# MCU_CTRL_MMR0_CFG0 register map
Vendor: Texas Instruments
Peripheral module from a debugger description file (folder J7VCL).
Registers are 32-bit, access per field, reset 0x0 unless marked. A register's access mark holds for its fields unless they carry their own. Offsets are as the file gives them; lines under a group give offsets from that group; [hi:lo] are bit positions; {n}, {i} and the like mark numbered series; 'fields as' and 'values as' point back to an identical list; <NAME> marks a mode.

## MCU_CTRL_MMR0_CFG0
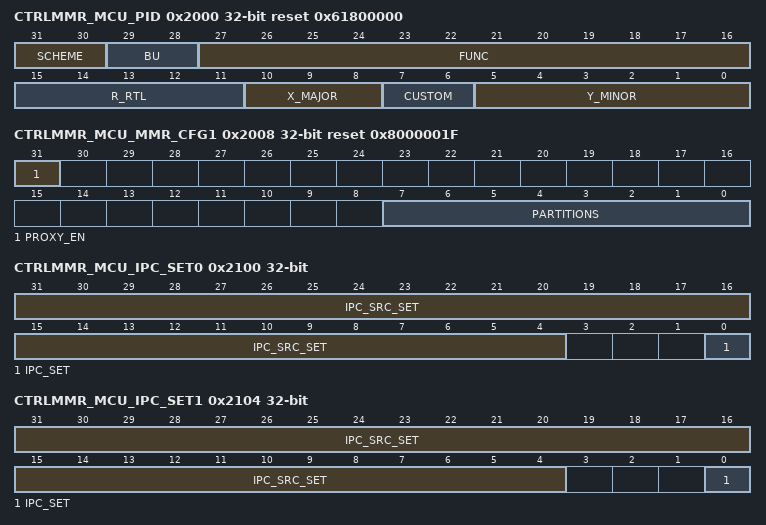
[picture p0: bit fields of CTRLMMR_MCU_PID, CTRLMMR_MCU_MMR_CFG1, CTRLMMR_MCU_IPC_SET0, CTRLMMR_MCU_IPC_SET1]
0x2000 CTRLMMR_MCU_PID ro reset 0x61800000
  [31:30] SCHEME
  [29:28] BU — Business unit - Processors
  [27:16] FUNC — Module functional identifier - CTRL MMR
  [15:11] R_RTL — RTL revision number
  [10:8] X_MAJOR — Major revision number
  [7:6] CUSTOM — Custom revision number
  [5:0] Y_MINOR — Minor revision number
0x2008 CTRLMMR_MCU_MMR_CFG1 ro reset 0x8000001F
  [31] PROXY_EN — Proxy addressing enabled
  [7:0] PARTITIONS — Indicates present partitions
0x2100 CTRLMMR_MCU_IPC_SET0 access not given
  [31:4] IPC_SRC_SET — Read returns current value (access W1TS)
  [0] IPC_SET — Read returns 0 (access W1TS)
0x2104 CTRLMMR_MCU_IPC_SET1 access not given
  fields as CTRLMMR_MCU_IPC_SET0
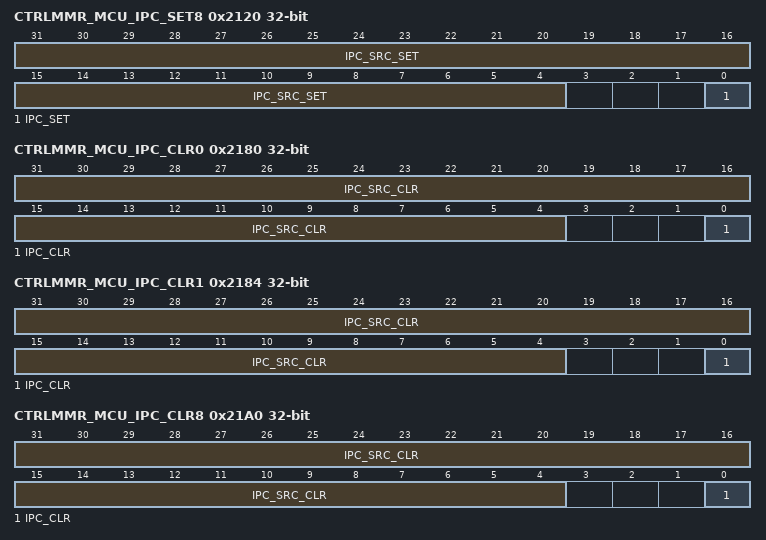
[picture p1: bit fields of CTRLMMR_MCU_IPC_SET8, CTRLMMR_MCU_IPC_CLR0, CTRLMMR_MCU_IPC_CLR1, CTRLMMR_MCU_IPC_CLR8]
0x2120 CTRLMMR_MCU_IPC_SET8 access not given
  fields as CTRLMMR_MCU_IPC_SET0
0x2180 CTRLMMR_MCU_IPC_CLR0 access not given
  [31:4] IPC_SRC_CLR — Read returns current value (access W1TC)
  [0] IPC_CLR — Read returns current value (access W1TC)
0x2184 CTRLMMR_MCU_IPC_CLR1 access not given
  fields as CTRLMMR_MCU_IPC_CLR0
0x21A0 CTRLMMR_MCU_IPC_CLR8 access not given
  fields as CTRLMMR_MCU_IPC_CLR0
0x2200 CTRLMMR_MCU_MAC_ID0 access not given reset not defined
  [31:0] MACID_LO — 32 lsbs of MAC address (access WOT)
0x2204 CTRLMMR_MCU_MAC_ID1 access not given (reset mask 0xFFFF0000)
  [15:0] MACID_HI — 16 msbs of MAC address (access WOT)
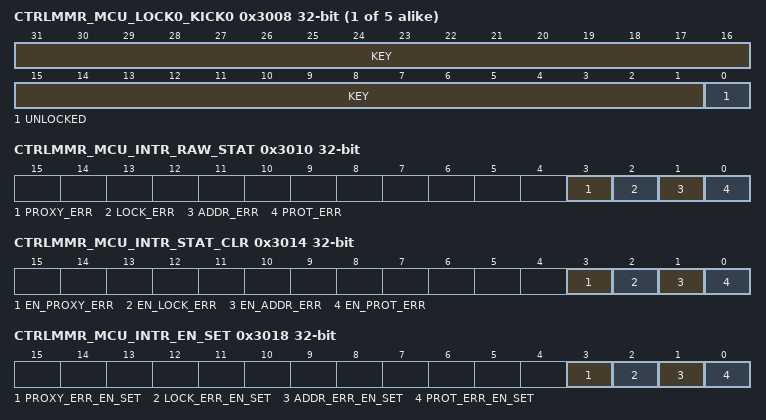
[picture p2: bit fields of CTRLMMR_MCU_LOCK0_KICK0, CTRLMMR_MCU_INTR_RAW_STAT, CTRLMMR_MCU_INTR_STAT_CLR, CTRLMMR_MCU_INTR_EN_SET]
{0x3008+0x4000*i} CTRLMMR_MCU_LOCK{i}_KICK0 (i=0..4)
  [31:1] KEY rw — Write the kick0 unlock value followed by the kick1 unlock value to unlock the write-protected Partition{i} registers
  [0] UNLOCKED ro — Unlock status. When set indicates that the proper unlock sequence has been performed and the partition is unlocked for writing.
{0x300C+0x4000*i} CTRLMMR_MCU_LOCK{i}_KICK1 rw (i=0..4)
  [31:0] KEY — Write the kick1 unlock value after the kick0 unlock value to unlock the write-protected Partition{i} registers
0x3010 CTRLMMR_MCU_INTR_RAW_STAT access not given
  [3] PROXY_ERR — Proxy violation occurred (attempt to write a Proxy1 claimed register through its Proxy0 address) (access W1TS)
  [2] LOCK_ERR — Lock violation occurred (attempt to write a write-locked register with partition locked) (access W1TS)
  [1] ADDR_ERR — Address violation occurred (attempt to read or write an invalid register address) (access W1TS)
  [0] PROT_ERR — Protection violation occurred (attempt to read or write a register with insufficient security or privilege access rights) (access W1TS)
0x3014 CTRLMMR_MCU_INTR_STAT_CLR access not given
  [3] EN_PROXY_ERR — Enabled proxy interrupt event status (access W1TC)
  [2] EN_LOCK_ERR — Enabled lock interrupt event status (access W1TC)
  [1] EN_ADDR_ERR — Enabled address interrupt event status (access W1TC)
  [0] EN_PROT_ERR — Enabled protection interrupt event status (access W1TC)
0x3018 CTRLMMR_MCU_INTR_EN_SET access not given
  [3] PROXY_ERR_EN_SET — Proxy interrupt enable (access W1TS)
  [2] LOCK_ERR_EN_SET — Lock interrupt enable (access W1TS)
  [1] ADDR_ERR_EN_SET — Address interrupt enable (access W1TS)
  [0] PROT_ERR_EN_SET — Protection interrupt enable (access W1TS)
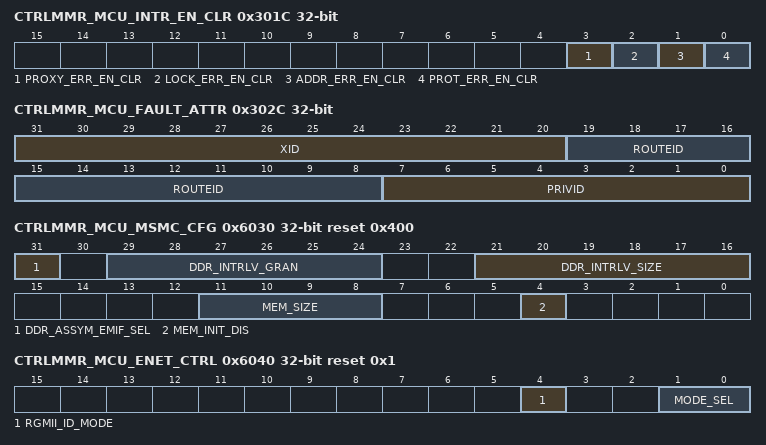
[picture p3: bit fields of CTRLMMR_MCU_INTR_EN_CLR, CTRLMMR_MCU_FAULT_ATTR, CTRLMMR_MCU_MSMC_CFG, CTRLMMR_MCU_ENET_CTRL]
0x301C CTRLMMR_MCU_INTR_EN_CLR access not given
  [3] PROXY_ERR_EN_CLR — Proxy interrupt disable (access W1TC)
  [2] LOCK_ERR_EN_CLR — Lock interrupt disable (access W1TC)
  [1] ADDR_ERR_EN_CLR — Address interrupt disable (access W1TC)
  [0] PROT_ERR_EN_CLR — Protection interrupt disable (access W1TC)
0x3020 CTRLMMR_MCU_EOI
  [7:0] VECTOR rw
0x3024 CTRLMMR_MCU_FAULT_ADDR ro
  [31:0] ADDRESS — Address of the faulted access
0x3028 CTRLMMR_MCU_FAULT_TYPE ro
  [5:0] TYPE — Type of access which faulted 0h - No fault 1h - User execute access 2h - User write access 4h - User read access 8h - Supervisor execute access 10h - Supervisor write access 20h - Supervisor read access
0x302C CTRLMMR_MCU_FAULT_ATTR ro
  [31:20] XID — Transaction ID
  [19:8] ROUTEID
  [7:0] PRIVID — Privilege ID
0x3030 CTRLMMR_MCU_FAULT_CLR access not given
  [0] CLEAR — Fault clear (access W1TC)
{0x3100+4i} CTRLMMR_MCU_P0_CLAIM{i} rw (i=0..4)
  [31:0] PROXY1_CLAIMED — Proxy1 register claim bit
0x6030 CTRLMMR_MCU_MSMC_CFG reset 0x400
  [31] DDR_ASSYM_EMIF_SEL rw — In the asymmetric interleave, controls which EMIF controller implements the separated range of the memory window
  [29:24] DDR_INTRLV_GRAN rw — Defines the size of each memory stripe for interleaved memory space
  [21:16] DDR_INTRLV_SIZE rw — Defines the memory window size for the interleaved region starting at the bottom of the external memory address range.
  [11:8] MEM_SIZE ro — Indicates the size of MSMC shared SRAM/Cache 0h - 0.0 MB 1h - 0.25 MB 2h - 0.5 MB 3h - 0.75 MB 4h - 1.0 MB 5h - 1.25 MB 6h - 1.5 MB 7h - 1.75 MB 8h - 2.0 MB
  [4] MEM_INIT_DIS rw — Disables MSMC SRAM initialization (Data, Cache Tags, and Snoop Filters). This is required for proper initial ECC initialization.
0x6040 CTRLMMR_MCU_ENET_CTRL reset 0x1
  [4] RGMII_ID_MODE rw — Port1 RGMII internal transmit delay selection
  [1:0] MODE_SEL rw — Selects Ethernet switch Port1 interface 0h - GMII/MII (not supported) 1h - RMII 2h - RGMII 3h - SGMII (not supported)
0x6060 CTRLMMR_MCU_SPI1_CTRL
  [0] SPI1_LINKDIS rw — Disables direct connection of MCU_SPI1 to SPI3 0h - MCU_SPI1 is tied as a slave to SPI3. MCU_SPI1 CLK, DATA1 and CS0 are driven from SPI3, DATA OUT drives SPI3 DATA0 1h - MCU_SPI1 is NOT tied as a slave to SPI3. MCU_SPI1 CLK, DATA0, DATA1 and CS[3:0] are controlled through their respective MCU_SPI1 pins and SPI3 CLK, DATA0, DATA1, and CS[3:0] are controlled through their respective SPI3 pins.
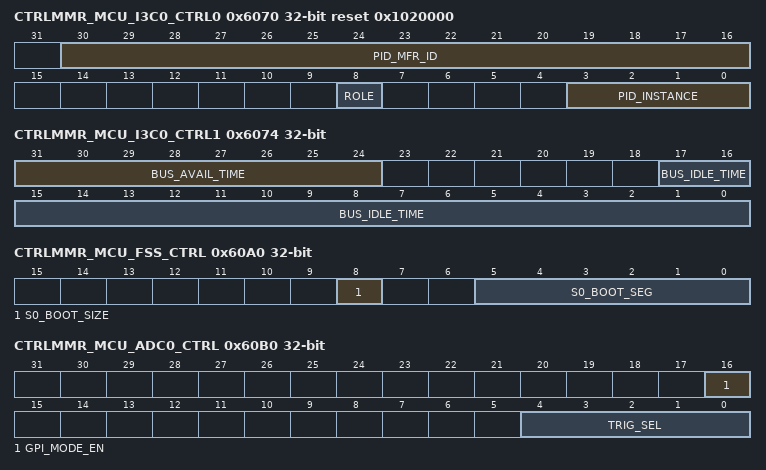
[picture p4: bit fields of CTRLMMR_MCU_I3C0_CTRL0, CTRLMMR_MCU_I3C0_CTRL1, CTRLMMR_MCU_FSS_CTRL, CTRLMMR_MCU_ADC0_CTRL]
0x6070 CTRLMMR_MCU_I3C0_CTRL0 reset 0x1020000
  [30:16] PID_MFR_ID rw — Manufacturer ID
  [8] ROLE rw — Master Role
  [3:0] PID_INSTANCE rw — Provisional ID Instance. This input corresponds to bits[15:12] of the Provisional ID. It is intended to provide a way of differentiating several I3C devices if there would be no other way to have each manufactured device have a unique Provisional ID
0x6074 CTRLMMR_MCU_I3C0_CTRL1
  [31:24] BUS_AVAIL_TIME rw — Indicates the number of pclk cycles in the Bus Available condition
  [17:0] BUS_IDLE_TIME rw — Indicates the number of pclk cycles in the Bus Idle condition
0x6080 CTRLMMR_MCU_I2C0_CTRL
  [0] HS_MCS_EN rw — HS Mode master current source enable.
0x6084 CTRLMMR_MCU_I2C1_CTRL
  [0] HS_MCS_EN rw — HS Mode master current source enable.
0x60A0 CTRLMMR_MCU_FSS_CTRL
  [8] S0_BOOT_SIZE rw — Selects the size of the boot block to be used for the S0 (OSPI0 or Hyperbus) flash interface
  [5:0] S0_BOOT_SEG rw — Selects the boot block to be used for the S0 (OSPI0 or Hyperbus) flash interface. If the s0_boot_size is 128 MB then only bits [4:0] of this field are used. Care must be taken to account for the address translation as to not fall off or wrap the address of the flash. (e.g. if both ECC and authentication are enabled for 64 MB boot, the highest valid block number is 49, as sector 50 is only .2M Bytes in size.)
0x60B0 CTRLMMR_MCU_ADC0_CTRL
  [16] GPI_MODE_EN rw — Enables MCU_ADC0 data pins to be used as general purpose inputs when set. This signal is tied to the en_dig_test input of MCU_ADC0
  [4:0] TRIG_SEL rw — Selects the source of the ADC hardware event trigger 0h - MCU_ADC_EXT_TRIGGER0 pin 1h - MCU_ADC_EXT_TRIGGER1 pin 2h - eHRPWM SOCA event 3h - eHRPWM SOCB event 4h - MCU Timer0 PWM output 5h - MCU Timer1 PWM output 6h - MCU Timer2 PWM output 7h - MCU Timer3 PWM output 8h - Timer0 PWM output 9h - Timer1 PWM output Ah - Timer2 PWM output Bh - Timer3 PWM output Ch - Timer4 PWM output Dh - Timer5 PWM output Eh - Timer6 PWM output Fh - Timer7 PWM output 10h - Timer8 PWM output 11h - Timer9 PWM output 12h - Timer10 PWM output 13h - Timer11 PWM output 15h - Reserved (tied 0h) 16h - Reserved (tied 0h) 18h - MCU Timer4 PWM output 19h - MCU Timer5 PWM output 1Ah - MCU Timer6 PWM output 1Bh - MCU Timer7 PWM output 1Ch - MCU Timer8 PWM output 1Dh - MCU Timer9 PWM output 1Eh - Reserved (tied 0h) 1Fh - Reserved (tied 0h)
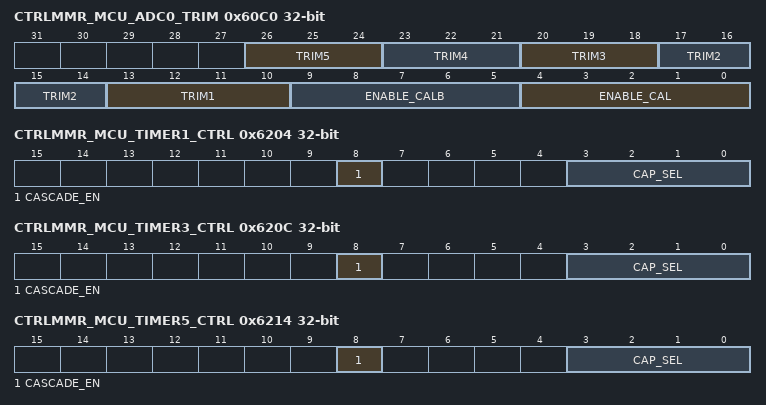
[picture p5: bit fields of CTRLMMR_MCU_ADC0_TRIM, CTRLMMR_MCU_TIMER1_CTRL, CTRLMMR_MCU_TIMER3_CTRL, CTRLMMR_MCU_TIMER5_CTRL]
0x60C0 CTRLMMR_MCU_ADC0_TRIM (reset mask 0xF8000000)
  [26:24] TRIM5 rw — Refer to AFE specification
  [23:21] TRIM4 rw — Refer to AFE specification
  [20:18] TRIM3 rw — Refer to AFE specification
  [17:14] TRIM2 rw — Refer to AFE specification
  [13:10] TRIM1 rw — Refer to AFE specification
  [9:5] ENABLE_CALB rw — Refer to AFE specification
  [4:0] ENABLE_CAL rw — Refer to AFE specification
0x6200 CTRLMMR_MCU_TIMER0_CTRL
  [3:0] CAP_SEL rw — Selects the MCU_TIMERIO input pin for capture input signal. This control is only used when TIMER0 is configured for capture operation. 0h - Use MCU_TIMER_IO0 pin 1h - Use MCU_TIMER_IO1 pin 2h - Use MCU_TIMER_IO2 pin 3h - Use MCU_TIMER_IO3 pin 4h - Use MCU_TIMER_IO4 pin 5h - Use MCU_TIMER_IO5 pin 6h - Use MCU_TIMER_IO6 pin 7h - Use MCU_TIMER_IO7 pin 8h - Use MCU_TIMER_IO8 pin 9h - Use MCU_TIMER_IO9 pin
0x6204 CTRLMMR_MCU_TIMER1_CTRL
  [8] CASCADE_EN rw — When set, enables cascading of MCU_TIMER1 to MCU_TIMER0
  [3:0] CAP_SEL rw — Selects the MCU_TIMERIO input pin for capture input signal. This control is only used when TIMER1 is configured for capture operation. 0h - Use MCU_TIMER_IO0 pin 1h - Use MCU_TIMER_IO1 pin 2h - Use MCU_TIMER_IO2 pin 3h - Use MCU_TIMER_IO3 pin 4h - Use MCU_TIMER_IO4 pin 5h - Use MCU_TIMER_IO5 pin 6h - Use MCU_TIMER_IO6 pin 7h - Use MCU_TIMER_IO7 pin 8h - Use MCU_TIMER_IO8 pin 9h - Use MCU_TIMER_IO9 pin
0x6208 CTRLMMR_MCU_TIMER2_CTRL
  [3:0] CAP_SEL rw — Selects the MCU_TIMERIO input pin for capture input signal. This control is only used when TIMER2 is configured for capture operation. 0h - Use MCU_TIMER_IO0 pin 1h - Use MCU_TIMER_IO1 pin 2h - Use MCU_TIMER_IO2 pin 3h - Use MCU_TIMER_IO3 pin 4h - Use MCU_TIMER_IO4 pin 5h - Use MCU_TIMER_IO5 pin 6h - Use MCU_TIMER_IO6 pin 7h - Use MCU_TIMER_IO7 pin 8h - Use MCU_TIMER_IO8 pin 9h - Use MCU_TIMER_IO9 pin
0x620C CTRLMMR_MCU_TIMER3_CTRL
  [8] CASCADE_EN rw — When set, enables cascading of MCU_TIMER3 to MCU_TIMER2
  [3:0] CAP_SEL rw — Selects the MCU_TIMERIO input pin for capture input signal. This control is only used when TIMER3 is configured for capture operation. 0h - Use MCU_TIMER_IO0 pin 1h - Use MCU_TIMER_IO1 pin 2h - Use MCU_TIMER_IO2 pin 3h - Use MCU_TIMER_IO3 pin 4h - Use MCU_TIMER_IO4 pin 5h - Use MCU_TIMER_IO5 pin 6h - Use MCU_TIMER_IO6 pin 7h - Use MCU_TIMER_IO7 pin 8h - Use MCU_TIMER_IO8 pin 9h - Use MCU_TIMER_IO9 pin
0x6210 CTRLMMR_MCU_TIMER4_CTRL
  [3:0] CAP_SEL rw — Selects the MCU_TIMERIO input pin for capture input signal. This control is only used when TIMER4 is configured for capture operation. 0h - Use MCU_TIMER_IO0 pin 1h - Use MCU_TIMER_IO1 pin 2h - Use MCU_TIMER_IO2 pin 3h - Use MCU_TIMER_IO3 pin 4h - Use MCU_TIMER_IO4 pin 5h - Use MCU_TIMER_IO5 pin 6h - Use MCU_TIMER_IO6 pin 7h - Use MCU_TIMER_IO7 pin 8h - Use MCU_TIMER_IO8 pin 9h - Use MCU_TIMER_IO9 pin
0x6214 CTRLMMR_MCU_TIMER5_CTRL
  [8] CASCADE_EN rw — When set, enables cascading of MCU_TIMER5 to MCU_TIMER4
  [3:0] CAP_SEL rw — Selects the MCU_TIMERIO input pin for capture input signal. This control is only used when TIMER5 is configured for capture operation. 0h - Use MCU_TIMER_IO0 pin 1h - Use MCU_TIMER_IO1 pin 2h - Use MCU_TIMER_IO2 pin 3h - Use MCU_TIMER_IO3 pin 4h - Use MCU_TIMER_IO4 pin 5h - Use MCU_TIMER_IO5 pin 6h - Use MCU_TIMER_IO6 pin 7h - Use MCU_TIMER_IO7 pin 8h - Use MCU_TIMER_IO8 pin 9h - Use MCU_TIMER_IO9 pin
0x6218 CTRLMMR_MCU_TIMER6_CTRL
  [3:0] CAP_SEL rw — Selects the MCU_TIMERIO input pin for capture input signal. This control is only used when TIMER6 is configured for capture operation. 0h - Use MCU_TIMER_IO0 pin 1h - Use MCU_TIMER_IO1 pin 2h - Use MCU_TIMER_IO2 pin 3h - Use MCU_TIMER_IO3 pin 4h - Use MCU_TIMER_IO4 pin 5h - Use MCU_TIMER_IO5 pin 6h - Use MCU_TIMER_IO6 pin 7h - Use MCU_TIMER_IO7 pin 8h - Use MCU_TIMER_IO8 pin 9h - Use MCU_TIMER_IO9 pin
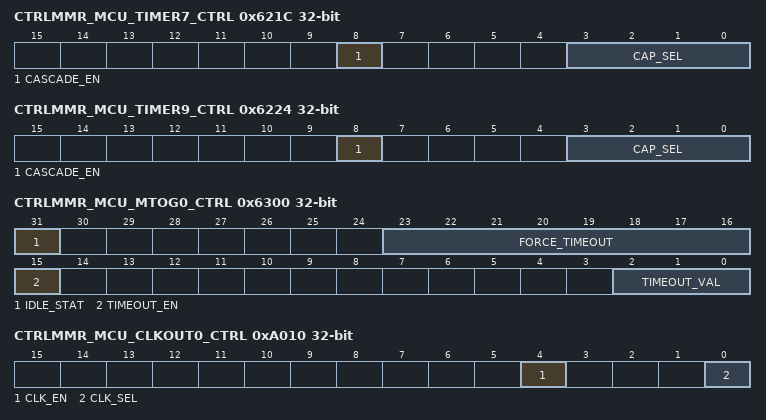
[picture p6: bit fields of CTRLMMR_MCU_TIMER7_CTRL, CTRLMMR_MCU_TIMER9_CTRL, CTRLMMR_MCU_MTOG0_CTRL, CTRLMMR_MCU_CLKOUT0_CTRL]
0x621C CTRLMMR_MCU_TIMER7_CTRL
  [8] CASCADE_EN rw — When set, enables cascading of MCU_TIMER7 to MCU_TIMER6
  [3:0] CAP_SEL rw — Selects the MCU_TIMERIO input pin for capture input signal. This control is only used when TIMER7 is configured for capture operation. 0h - Use MCU_TIMER_IO0 pin 1h - Use MCU_TIMER_IO1 pin 2h - Use MCU_TIMER_IO2 pin 3h - Use MCU_TIMER_IO3 pin 4h - Use MCU_TIMER_IO4 pin 5h - Use MCU_TIMER_IO5 pin 6h - Use MCU_TIMER_IO6 pin 7h - Use MCU_TIMER_IO7 pin 8h - Use MCU_TIMER_IO8 pin 9h - Use MCU_TIMER_IO9 pin
0x6220 CTRLMMR_MCU_TIMER8_CTRL
  [3:0] CAP_SEL rw — Selects the MCU_TIMERIO input pin for capture input signal. This control is only used when TIMER8 is configured for capture operation. 0h - Use MCU_TIMER_IO0 pin 1h - Use MCU_TIMER_IO1 pin 2h - Use MCU_TIMER_IO2 pin 3h - Use MCU_TIMER_IO3 pin 4h - Use MCU_TIMER_IO4 pin 5h - Use MCU_TIMER_IO5 pin 6h - Use MCU_TIMER_IO6 pin 7h - Use MCU_TIMER_IO7 pin 8h - Use MCU_TIMER_IO8 pin 9h - Use MCU_TIMER_IO9 pin
0x6224 CTRLMMR_MCU_TIMER9_CTRL
  [8] CASCADE_EN rw — When set, enables cascading of MCU_TIMER9 to MCU_TIMER8
  [3:0] CAP_SEL rw — Selects the MCU_TIMERIO input pin for capture input signal. This control is only used when TIMER9 is configured for capture operation. 0h - Use MCU_TIMER_IO0 pin 1h - Use MCU_TIMER_IO1 pin 2h - Use MCU_TIMER_IO2 pin 3h - Use MCU_TIMER_IO3 pin 4h - Use MCU_TIMER_IO4 pin 5h - Use MCU_TIMER_IO5 pin 6h - Use MCU_TIMER_IO6 pin 7h - Use MCU_TIMER_IO7 pin 8h - Use MCU_TIMER_IO8 pin 9h - Use MCU_TIMER_IO9 pin
{0x6280+4i} CTRLMMR_MCU_TIMERIO{i}_CTRL reset 0xF (i=0..9)
  [3:0] OUT_SEL rw — Selects the source of the MCU_TIMERIO{i} output 0h - MCU_TIMERIO{i} is driven by MCU_TIMER0 output 1h - MCU_TIMERIO{i} is driven by MCU_TIMER1 output 2h - MCU_TIMERIO{i} is driven by MCU_TIMER2 output 3h - MCU_TIMERIO{i} is driven by MCU_TIMER3 output 4h - MCU_TIMERIO{i} is driven by MCU_TIMER4 output 5h - MCU_TIMERIO{i} is driven by MCU_TIMER5 output 6h - MCU_TIMERIO{i} is driven by MCU_TIMER6 output 7h - MCU_TIMERIO{i} is driven by MCU_TIMER7 output 8h - MCU_TIMERIO{i} is driven by MCU_TIMER8 output 9h - MCU_TIMERIO{i} is driven by MCU_TIMER9 output Ah - MCU_TIMERIO{i} is driven low Bh - MCU_TIMERIO{i} is driven high Ch - MCU_TIMERIO{i} is driven low Dh - MCU_TIMERIO{i} is driven high Eh - MCU_TIMERIO{i} is driven low Fh - MCU_TIMERIO{i} is driven high
0x6300 CTRLMMR_MCU_MTOG0_CTRL (reset mask 0x7FFFFFFF)
  [31] IDLE_STAT ro — Idle status
  [23:16] FORCE_TIMEOUT rw
  [15] TIMEOUT_EN rw — Timeout Enable
  [2:0] TIMEOUT_VAL rw — Gasket Timeout Value 0h - 1024 clock cycles 1h - 4096 clock cycles 2h - 16,384 clock cycles 3h - 65,536 clock cycles 4h - 262,144 clock cycles 5h - 1,048,576 clock cycles 6h - 2,097,152 clock cycles 7h - 4,194,303 clock cycles
{0x7100+4i} CTRLMMR_MCU_P1_CLAIM{i} rw (i=0..6)
  [31:0] PROXY1_CLAIMED — Proxy1 register claim bit
0xA010 CTRLMMR_MCU_CLKOUT0_CTRL
  [4] CLK_EN rw — When set, enables MCU_CLKOUT0 output
  [0] CLK_SEL rw — Selects MCU_CLKOUT0 clock source
0xA018 CTRLMMR_MCU_EFUSE_CLKSEL
  [0] CLK_SEL rw — Selects the clock source 0h - EFUSE_CLK (HFOSC0_CLKOUT or CLK_12M_RC) 1h - MCU_SYSCLK0 / 8
0xA020 CTRLMMR_MCU_MCAN0_CLKSEL
  [1:0] CLK_SEL rw — MCU_MCAN MCAN_CLK selection
0xA024 CTRLMMR_MCU_MCAN1_CLKSEL
  [1:0] CLK_SEL rw — MCU_MCAN MCAN_CLK selection
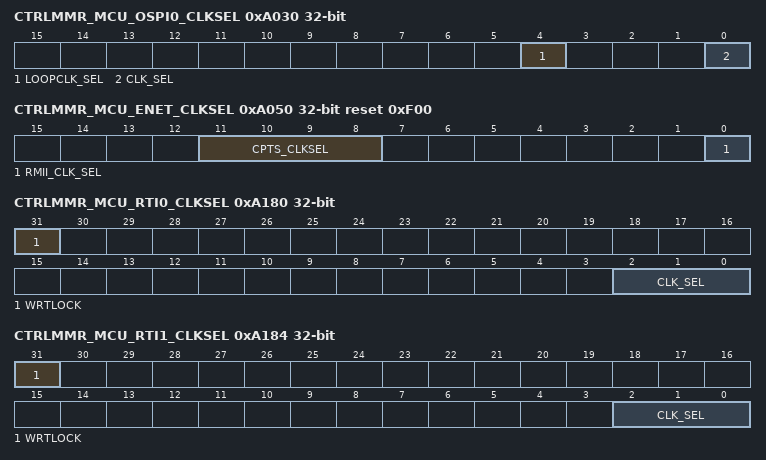
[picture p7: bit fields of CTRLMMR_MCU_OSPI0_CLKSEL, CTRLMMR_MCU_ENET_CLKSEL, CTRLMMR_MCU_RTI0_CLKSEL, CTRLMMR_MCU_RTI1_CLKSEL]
0xA030 CTRLMMR_MCU_OSPI0_CLKSEL
  [4] LOOPCLK_SEL rw — OBSPI0 Loopback clock source
  [0] CLK_SEL rw — OSPI0 reference clock selection
0xA040 CTRLMMR_MCU_ADC0_CLKSEL
  [1:0] CLK_SEL rw — Selects the sampling clock source for ADC0 0h - HFOSC0_CLKOUT 1h - MCU_PLL1_HSDIV1_CLKOUT1 2h - MCU_PLL0_HSDIV1_CLKOUT1 3h - MCU_EXT_REFCLK0
0xA050 CTRLMMR_MCU_ENET_CLKSEL reset 0xF00
  [11:8] CPTS_CLKSEL rw — Selects the clock source for the CPSW2x Ethernet switch Common Platform Time Stamp module 0h - MAIN_PLL3_HSDIV1_CLKOUT 1h - MAIN_PLL0_HSDIV6_CLKOUT 2h - MCU_CPTS_REF_CLK (pin) 3h - CPTS_RFT_CLK (pin) 4h - MCU_EXT_REFCLK0 (pin) 5h - EXT_REFCLK1 (pin) 6h - SERDES0_IP2_LN0_TXMCLK 7h - SERDES0_IP2_LN1_TXMCLK 8h - SERDES0_IP2_LN2_TXMCLK 9h - SERDES0_IP2_LN3_TXMCLK Ah - SERDES4_IP2_LN0_TXMCLK Bh - SERDES4_IP2_LN1_TXMCLK Ch - SERDES4_IP2_LN2_TXMCLK Dh - SERDES4_IP2_LN3_TXMCLK Eh - MCU_PLL2_HSDIV1_CLKOUT Fh - MAIN_SYSCLK0 / 2
  [0] RMII_CLK_SEL rw — Selects the rmii clock (rmii_mhz_50_clk) source. This defaults to the internal 50 MHz clock source for proper clockstop operation
0xA080 CTRLMMR_MCU_R5_CORE0_CLKSEL
  [0] CLK_SEL rw — Selects the Core 0 functional clock and mcu/interface clock ratio.
{0xA100+4i} CTRLMMR_MCU_TIMER{i}_CLKSEL (i=0..9)
  [2:0] CLK_SEL rw — Timer functional clock input select mux control 0h - HFOSC0_CLKOUT 1h - MCU_SYSCLK0 / 4 2h - CLK_12M_RC 3h - MCU_PLL2_HSDIV2_CLKOUT 4h - MCU_EXT_REFCLK0 5h - LFXOSC_CLKOUT 6h - CPSW_GENF0 7h - CLK_32K
0xA180 CTRLMMR_MCU_RTI0_CLKSEL
  [31] WRTLOCK rw — When set, locks further writes to
  [2:0] CLK_SEL rw — RTI functional clock input select mux control 0h - HFOSC0_CLKOUT 1h - LFXOSC_CLKOUT 2h - CLK_12M_RC 3h - CLK_32K
0xA184 CTRLMMR_MCU_RTI1_CLKSEL
  fields as CTRLMMR_MCU_RTI0_CLKSEL
0xA1C0 CTRLMMR_MCU_USART_CLKSEL
  [0] CLK_SEL rw — MCU_USART0 FCLK selection
{0xB100+4i} CTRLMMR_MCU_P2_CLAIM{i} rw (i=0..3)
  [31:0] PROXY1_CLAIMED — Proxy1 register claim bit
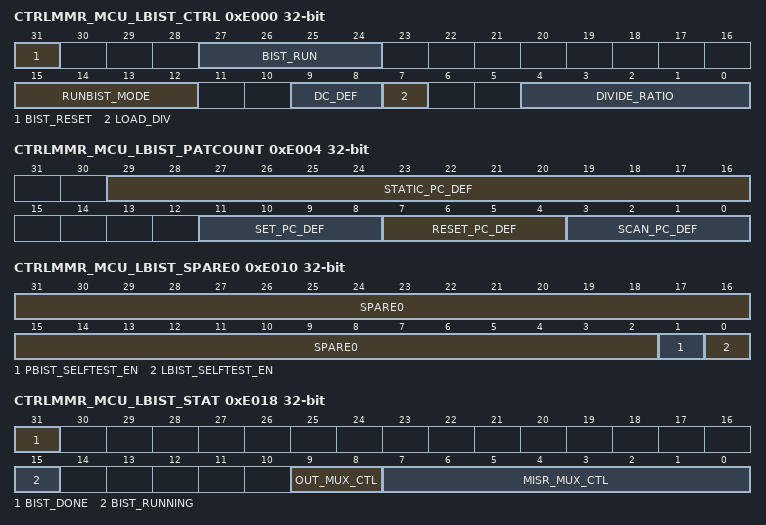
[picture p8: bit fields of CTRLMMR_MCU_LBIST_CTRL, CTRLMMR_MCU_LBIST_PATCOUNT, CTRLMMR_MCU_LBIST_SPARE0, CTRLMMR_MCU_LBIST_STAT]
0xE000 CTRLMMR_MCU_LBIST_CTRL (reset mask 0x70FF0C60)
  [31] BIST_RESET rw — Reset LBIST macro
  [27:24] BIST_RUN rw — Starts LBIST if all bits are 1
  [15:12] RUNBIST_MODE rw — Runbist mode enable if all bits are 1
  [9:8] DC_DEF rw — Clock delay after scan_enable switching
  [7] LOAD_DIV rw — Loads LBIST clock divide ratio on transition from 0 to 1
  [4:0] DIVIDE_RATIO rw — LBIST clock divide ratio
0xE004 CTRLMMR_MCU_LBIST_PATCOUNT (reset mask 0xC000F000)
  [29:16] STATIC_PC_DEF rw — Number of stuck-at patterns to run
  [11:8] SET_PC_DEF rw — Number of set patterns to run
  [7:4] RESET_PC_DEF rw — Number of reset patterns to run
  [3:0] SCAN_PC_DEF rw — Number of chain test patterns to run
0xE008 CTRLMMR_MCU_LBIST_SEED0 rw reset not defined
  [31:0] PRPG_DEF — Initial seed for PRPG (bits 31:0)
0xE00C CTRLMMR_MCU_LBIST_SEED1 (reset mask 0xFFE00000)
  [20:0] PRPG_DEF rw — Initial seed for PRPG (bits 52:32)
0xE010 CTRLMMR_MCU_LBIST_SPARE0 rw
  [31:2] SPARE0 — LBIST spare bits
  [1] PBIST_SELFTEST_EN — PBIST isolation control
  [0] LBIST_SELFTEST_EN — LBIST isolation control
0xE014 CTRLMMR_MCU_LBIST_SPARE1 rw
  [31:0] SPARE1 — LBIST spare bits
0xE018 CTRLMMR_MCU_LBIST_STAT (reset mask 0x7FFF7FFF)
  [31] BIST_DONE ro — LBIST is done
  [15] BIST_RUNNING ro — LBIST is running
  [9:8] OUT_MUX_CTL rw — Selects source of LBIST output
  [7:0] MISR_MUX_CTL rw — Selects block of 32 MISR bits to read. A value of 0 selects a compacted 32-bit version of the full MISR. A value of 1-32 select a 32-bit segment of the MISR.
0xE01C CTRLMMR_MCU_LBIST_MISR ro reset not defined
  [31:0] MISR_RESULT — 32-bits of MISR value selected by misr_mux_ctl
0xE280 CTRLMMR_MCU_LBIST_SIG ro reset not defined
  [31:0] MISR_SIG — MISR signature
{0xF100+4i} CTRLMMR_MCU_P3_CLAIM{i} rw (i=0..5)
  [31:0] PROXY1_CLAIMED — Proxy1 register claim bit
{0x13100+4i} CTRLMMR_MCU_P4_CLAIM{i} rw (i=0..6)
  [31:0] PROXY1_CLAIMED — Proxy1 register claim bit
